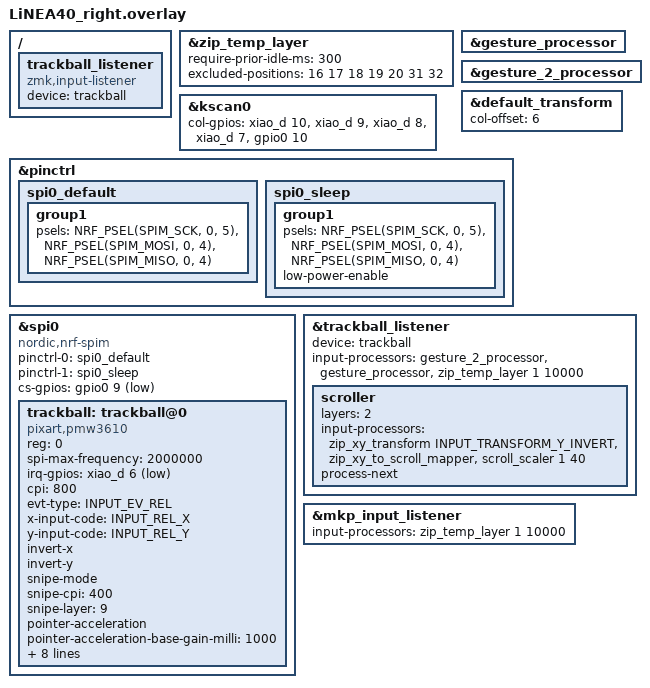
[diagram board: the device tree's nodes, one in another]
#include "LiNEA40.dtsi"
#include <input/processors.dtsi>
#include <dt-bindings/zmk/input_transform.h>
#include <zephyr/dt-bindings/input/input-event-codes.h>

/* Reuse ZMK's single temp-layer processor for Auto Mouse Layer. */
&zip_temp_layer {
    require-prior-idle-ms = <300>;
    excluded-positions = <16 17 18 19 20 31 32>;
};

&gesture_processor {
    status = "okay";
};

&gesture_2_processor {
    status = "okay";
};

&default_transform {
    col-offset = <6>;
};

&kscan0 {
    col-gpios
        = <&xiao_d 10 GPIO_ACTIVE_HIGH> //col0-D10
        , <&xiao_d 9 GPIO_ACTIVE_HIGH>  //col1-D9
        , <&xiao_d 8 GPIO_ACTIVE_HIGH>  //col2-D8
        , <&xiao_d 7 GPIO_ACTIVE_HIGH>  //col3-D7
        , <&gpio0 10 GPIO_ACTIVE_HIGH>  //col4-NFC2
        ;
};

/ {
    trackball_listener {
        compatible = "zmk,input-listener";
        device = <&trackball>;

    };
};


&pinctrl {
    spi0_default: spi0_default {
        group1 {
            psels = <NRF_PSEL(SPIM_SCK, 0, 5)>   // SCLK-D5
                  , <NRF_PSEL(SPIM_MOSI, 0, 4)>  // SDIO-D4
                  , <NRF_PSEL(SPIM_MISO, 0, 4)>  // SDIO-D4
                  ;
        };
    };

    spi0_sleep: spi0_sleep {
        group1 {
            psels = <NRF_PSEL(SPIM_SCK, 0, 5)>   // SCLK-D5
                  , <NRF_PSEL(SPIM_MOSI, 0, 4)>  // SDIO-D4
                  , <NRF_PSEL(SPIM_MISO, 0, 4)>  // SDIO-D4
                  ;
            low-power-enable;
        };
    };
};

&spi0 {
    status = "okay";
    compatible = "nordic,nrf-spim";
    pinctrl-0 = <&spi0_default>;
    pinctrl-1 = <&spi0_sleep>;
    pinctrl-names = "default", "sleep";
    cs-gpios = <&gpio0 9 GPIO_ACTIVE_LOW>; //NCS-NFC1

    trackball: trackball@0 {
        status = "okay";
        compatible = "pixart,pmw3610";
        reg = <0>;
        spi-max-frequency = <2000000>;
        irq-gpios = <&xiao_d 6 (GPIO_ACTIVE_LOW | GPIO_PULL_UP)>; //MOT-D6
        cpi = <800>;
        evt-type = <INPUT_EV_REL>;
        x-input-code = <INPUT_REL_X>;
        y-input-code = <INPUT_REL_Y>;
        invert-x;
        invert-y;

        /* Preserve LiNEA40's hardware 400-CPI Precision layer. */
        snipe-mode;
        snipe-cpi = <400>;
        snipe-layer = <9>;

        /* 14-mm LisM pre-19-mm curve, converted from 1000 to 800 CPI. */
        pointer-acceleration;
        pointer-acceleration-base-gain-milli = <1000>;
        pointer-acceleration-takeoff-speed = <14>;
        pointer-acceleration-full-speed = <68>;
        pointer-acceleration-max-gain-milli = <3000>;
        pointer-acceleration-reference-interval-ms = <8>;
        pointer-acceleration-idle-reset-ms = <60>;
        pointer-acceleration-scroll-layer = <2>;
        pointer-acceleration-gesture-layer = <3>;
        pointer-acceleration-gesture-layer-2 = <4>;
    };
};

&trackball_listener {
    status = "okay";
    device = <&trackball>;

    input-processors =
        <&gesture_2_processor>,
        <&gesture_processor>,
        <&zip_temp_layer 1 10000>;

    scroller {
        layers = <2>;
        input-processors =
            <&zip_xy_transform INPUT_TRANSFORM_Y_INVERT>,
            <&zip_xy_to_scroll_mapper>,
            <&scroll_scaler 1 40>;
        process-next;
    };
};

/* Mouse-button activity refreshes AML while pointer motion owns activation. */
&mkp_input_listener {
    input-processors = <&zip_temp_layer 1 10000>;
};
